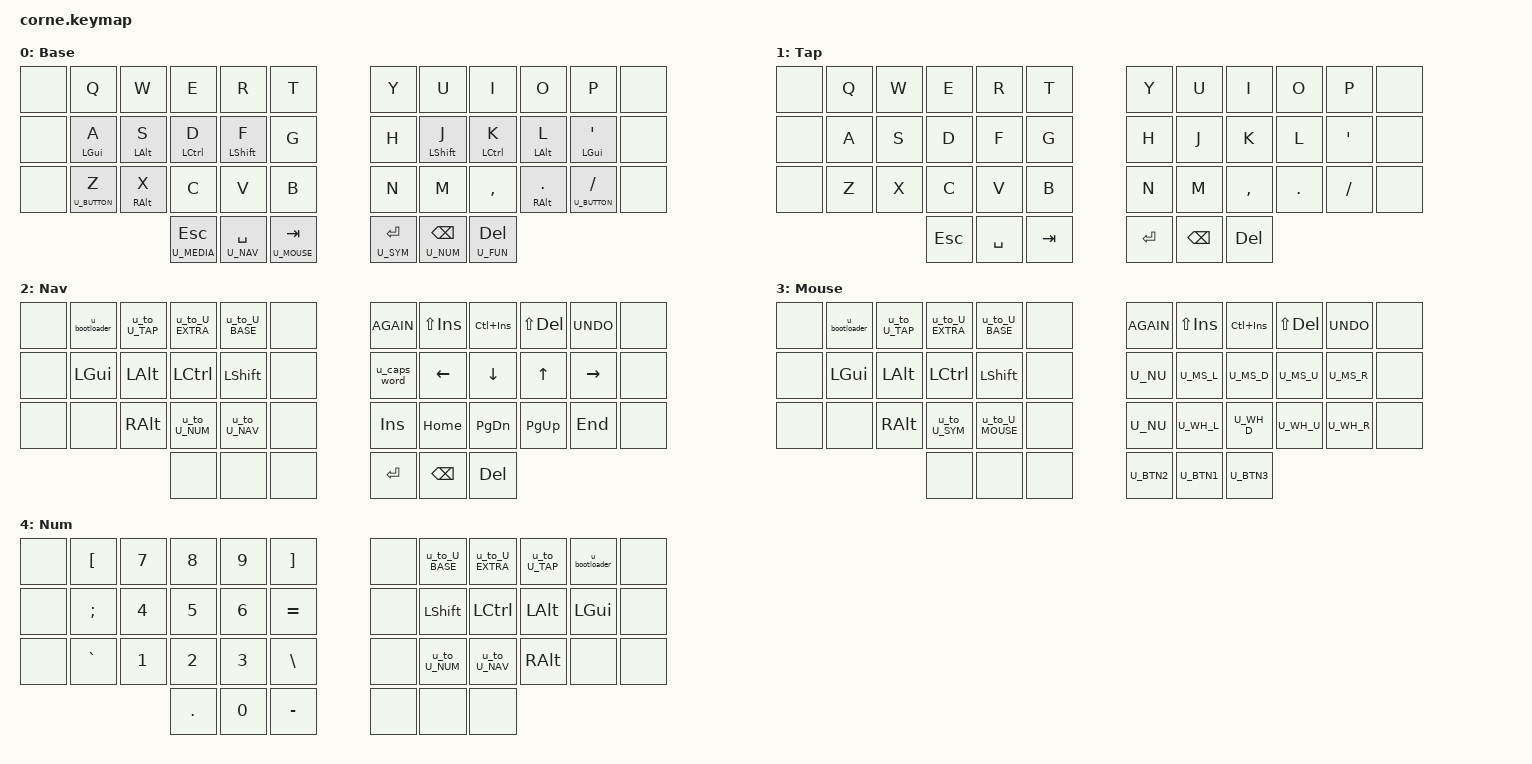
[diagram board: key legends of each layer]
#include <behaviors.dtsi>
#include <dt-bindings/zmk/keys.h>
#include <dt-bindings/zmk/bt.h>

#define U_BASE   0
#define U_EXTRA  1
#define U_TAP    2
#define U_BUTTON 3
#define U_NAV    4
#define U_MOUSE  5
#define U_MEDIA  6
#define U_NUM    7
#define U_SYM    8
#define U_FUN    9

#define U_TAPPING_TERM 0xc8

#define U_RDO &kp K_AGAIN
#define U_PST &kp LS(INS)
#define U_CPY &kp LC(INS)
#define U_CUT &kp LS(DEL)
#define U_UND &kp K_UNDO

&mt {
	flavor = "tap-preferred";
	tapping-term-ms = <U_TAPPING_TERM>;
};

&lt {
	flavor = "tap-preferred";
	tapping-term-ms = <U_TAPPING_TERM>;
};

/ {
	behaviors {
		u_bootloader: u_bootloader {
			compatible = "zmk,behavior-tap-dance";
			#binding-cells = <0>;
			tapping-term-ms = <U_TAPPING_TERM>;
			bindings = <&none>, <&bootloader>;
		};

		u_to_U_BASE: u_to_U_BASE {
			compatible = "zmk,behavior-tap-dance";
			#binding-cells = <0>;
			tapping-term-ms = <U_TAPPING_TERM>;
			bindings = <&none>, <&to U_BASE>;
		};

		u_to_U_EXTRA: u_to_U_EXTRA {
			compatible = "zmk,behavior-tap-dance";
			#binding-cells = <0>;
			tapping-term-ms = <U_TAPPING_TERM>;
			bindings = <&none>, <&to U_EXTRA>;
		};

		u_to_U_TAP: u_to_U_TAP {
			compatible = "zmk,behavior-tap-dance";
			#binding-cells = <0>;
			tapping-term-ms = <U_TAPPING_TERM>;
			bindings = <&none>, <&to U_TAP>;
		};

		u_to_U_BUTTON: u_to_U_BUTTON {
			compatible = "zmk,behavior-tap-dance";
			#binding-cells = <0>;
			tapping-term-ms = <U_TAPPING_TERM>;
			bindings = <&none>, <&to U_BUTTON>;
		};

		u_to_U_NAV: u_to_U_NAV {
			compatible = "zmk,behavior-tap-dance";
			#binding-cells = <0>;
			tapping-term-ms = <U_TAPPING_TERM>;
			bindings = <&none>, <&to U_NAV>;
		};

		u_to_U_MOUSE: u_to_U_MOUSE {
			compatible = "zmk,behavior-tap-dance";
			#binding-cells = <0>;
			tapping-term-ms = <U_TAPPING_TERM>;
			bindings = <&none>, < &to U_MOUSE >;
		};

		u_to_U_MEDIA: u_to_U_MEDIA {
			compatible = "zmk,behavior-tap-dance";
			#binding-cells = <0>;
			tapping-term-ms = <U_TAPPING_TERM>;
			bindings = <&none>, < &to U_MEDIA >;
		};

		u_to_U_NUM: u_to_U_NUM {
			compatible = "zmk,behavior-tap-dance";
			#binding-cells = <0>;
			tapping-term-ms = <U_TAPPING_TERM>;
			bindings = <&none>, < &to U_NUM >;
		};

		u_to_U_SYM: u_to_U_SYM {
			compatible = "zmk,behavior-tap-dance";
			#binding-cells = <0>;
			tapping-term-ms = <U_TAPPING_TERM>;
			bindings = <&none>, < &to U_SYM >;
		};

		u_to_U_FUN: u_to_U_FUN {
			compatible = "zmk,behavior-tap-dance";
			#binding-cells = <0>;
			tapping-term-ms = <U_TAPPING_TERM>;
			bindings = <&none>, < &to U_FUN >;
		};
	};

	keymap {
		compatible = "zmk,keymap";

		base_layer {
			display-name = "Base";
			bindings = <
&none  &kp Q           &kp W       &kp E        &kp R        &kp T    &kp Y  &kp U        &kp I        &kp O         &kp P              &none
&none  &mt LGUI A      &mt LALT S  &mt LCTRL D  &mt LSHFT F  &kp G    &kp H  &mt LSHFT J  &mt LCTRL K  &mt LALT L    &mt LGUI SQT       &none
&none  &lt U_BUTTON Z  &mt RALT X  &kp C        &kp V        &kp B    &kp N  &kp M        &kp COMMA    &mt RALT DOT  &lt U_BUTTON FSLH  &none

				&lt U_MEDIA ESC  &lt U_NAV SPACE  &lt U_MOUSE TAB    &lt U_SYM RET  &lt U_NUM BSPC  &lt U_FUN DEL
			>;
		};

		/*
		extra_layer {
			display-name = "Extra";
			bindings = <>;
		};
		*/
		tap_layer {
			display-name = "Tap";
			bindings = <
&none  &kp Q  &kp W  &kp E  &kp R  &kp T    &kp Y  &kp U  &kp I      &kp O    &kp P      &none
&none  &kp A  &kp S  &kp D  &kp F  &kp G    &kp H  &kp J  &kp K      &kp L    &kp SQT    &none
&none  &kp Z  &kp X  &kp C  &kp V  &kp B    &kp N  &kp M  &kp COMMA  &kp DOT  &kp SLASH  &none

				&kp ESC  &kp SPACE  &kp TAB    &kp RET  &kp BSPC  &kp DEL			
			
			>;
		};
		/*
		button_layer {
			display-name = "Button";
			bindings = <>;
		};
		*/
		nav_layer {
			display-name = "Nav";
			bindings = <
&none  &u_bootloader  &u_to_U_TAP  &u_to_U_EXTRA  &u_to_U_BASE  &none      U_RDO         U_PST     U_CPY      U_CUT      U_UND      &none
&none  &kp LGUI       &kp LALT     &kp LCTRL      &kp LSHFT     &none      &u_caps_word  &kp LEFT  &kp DOWN   &kp UP     &kp RIGHT  &none
&none  &none          &kp RALT     &u_to_U_NUM    &u_to_U_NAV   &none      &kp INS       &kp HOME  &kp PG_DN  &kp PG_UP  &kp END    &none

				&none  &none  &none      &kp RET       &kp BSPC   &kp DEL
			>;
		};

		mouse_layer {
			display-name = "Mouse";
			bindings = <
&none  &u_bootloader  &u_to_U_TAP  &u_to_U_EXTRA  &u_to_U_BASE   &none    U_RDO  U_PST   U_CPY   U_CUT   U_UND   &none
&none  &kp LGUI       &kp LALT     &kp LCTRL      &kp LSHFT      &none    U_NU   U_MS_L  U_MS_D  U_MS_U  U_MS_R  &none
&none  &none          &kp RALT     &u_to_U_SYM    &u_to_U_MOUSE  &none    U_NU   U_WH_L  U_WH_D  U_WH_U  U_WH_R  &none

 				&none  &none  &none   U_BTN2  U_BTN1  U_BTN3
			>;
		};
		/*
		media_layer {
			display-name = "Media";
			bindings = <>;
		};
		*/
		num_layer {
			display-name = "Num";
			bindings = <
&none  &kp LBKT  &kp N7  &kp N8  &kp N9  &kp RBKT    &none  &u_to_U_BASE  &u_to_U_EXTRA  &u_to_U_TAP  &u_bootloader  &none
&none  &kp SEMI  &kp N4  &kp N5  &kp N6  &kp EQUAL   &none  &kp LSHFT     &kp LCTRL      &kp LALT     &kp LGUI       &none
&none  &kp GRAVE &kp N1  &kp N2  &kp N3  &kp BSLH    &none  &u_to_U_NUM   &u_to_U_NAV    &kp RALT     &none          &none

				&kp DOT  &kp N0  &kp MINUS     &none   &none  &none
			>;
		};
		/*
		sym_layer {
			display-name = "Sym";
			bindings = <>;
		};
		fun_layer {
			display-name = "Fun";
			bindings = <>;
		};
		*/

	};
};
